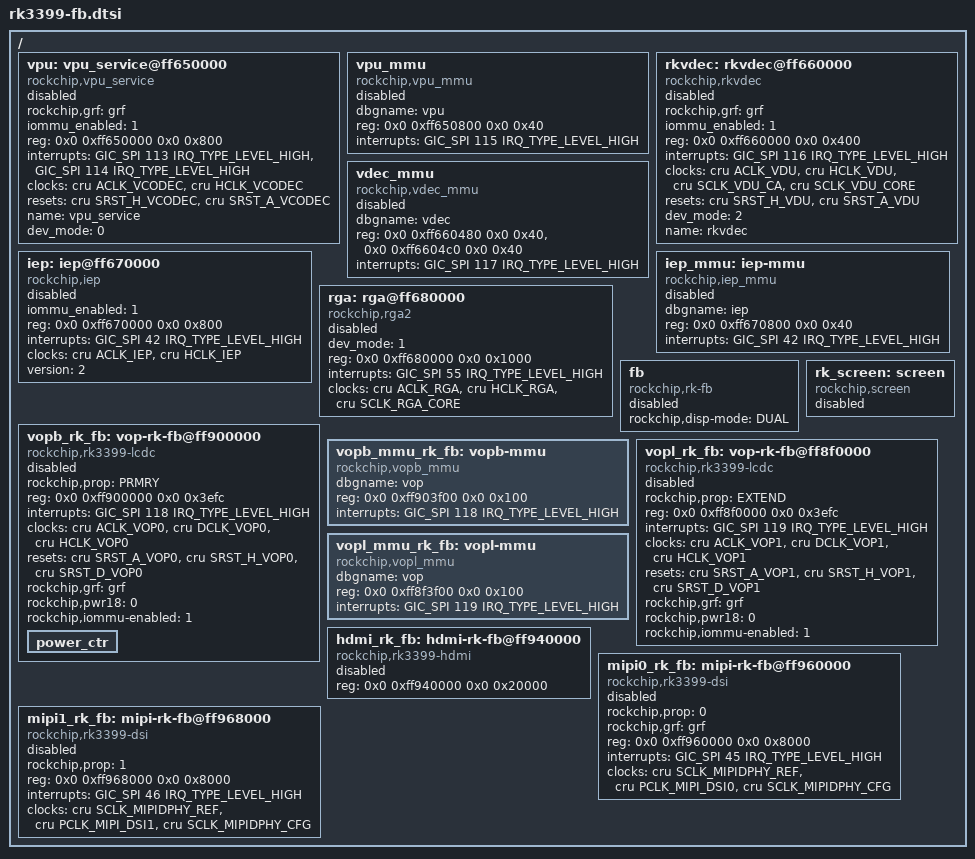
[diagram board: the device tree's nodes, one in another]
/*
 * Copyright (c) 2016 Fuzhou Rockchip Electronics Co., Ltd
 *
 * This file is dual-licensed: you can use it either under the terms
 * of the GPL or the X11 license, at your option. Note that this dual
 * licensing only applies to this file, and not this project as a
 * whole.
 *
 *  a) This file is free software; you can redistribute it and/or
 *     modify it under the terms of the GNU General Public License as
 *     published by the Free Software Foundation; either version 2 of the
 *     License, or (at your option) any later version.
 *
 *     This file is distributed in the hope that it will be useful,
 *     but WITHOUT ANY WARRANTY; without even the implied warranty of
 *     MERCHANTABILITY or FITNESS FOR A PARTICULAR PURPOSE.  See the
 *     GNU General Public License for more details.
 *
 * Or, alternatively,
 *
 *  b) Permission is hereby granted, free of charge, to any person
 *     obtaining a copy of this software and associated documentation
 *     files (the "Software"), to deal in the Software without
 *     restriction, including without limitation the rights to use,
 *     copy, modify, merge, publish, distribute, sublicense, and/or
 *     sell copies of the Software, and to permit persons to whom the
 *     Software is furnished to do so, subject to the following
 *     conditions:
 *
 *     The above copyright notice and this permission notice shall be
 *     included in all copies or substantial portions of the Software.
 *
 *     THE SOFTWARE IS PROVIDED "AS IS", WITHOUT WARRANTY OF ANY KIND,
 *     EXPRESS OR IMPLIED, INCLUDING BUT NOT LIMITED TO THE WARRANTIES
 *     OF MERCHANTABILITY, FITNESS FOR A PARTICULAR PURPOSE AND
 *     NONINFRINGEMENT. IN NO EVENT SHALL THE AUTHORS OR COPYRIGHT
 *     HOLDERS BE LIABLE FOR ANY CLAIM, DAMAGES OR OTHER LIABILITY,
 *     WHETHER IN AN ACTION OF CONTRACT, TORT OR OTHERWISE, ARISING
 *     FROM, OUT OF OR IN CONNECTION WITH THE SOFTWARE OR THE USE OR
 *     OTHER DEALINGS IN THE SOFTWARE.
 */
#include <dt-bindings/display/rk_fb.h>
#include <dt-bindings/display/mipi_dsi.h>

/ {
	vpu: vpu_service@ff650000 {
		compatible = "rockchip,vpu_service";
		rockchip,grf = <&grf>;
		iommu_enabled = <1>;
		reg = <0x0 0xff650000 0x0 0x800>;
		interrupts = <GIC_SPI 113 IRQ_TYPE_LEVEL_HIGH>,
			<GIC_SPI 114 IRQ_TYPE_LEVEL_HIGH>;
		interrupt-names = "irq_dec", "irq_enc";
		clocks = <&cru ACLK_VCODEC>, <&cru HCLK_VCODEC>;
		clock-names = "aclk_vcodec", "hclk_vcodec";
		resets = <&cru SRST_H_VCODEC>, <&cru SRST_A_VCODEC>;
		reset-names = "video_h", "video_a";
		name = "vpu_service";
		dev_mode = <0>;
		status = "disabled";
	};

	vpu_mmu: vpu_mmu {
		dbgname = "vpu";
		compatible = "rockchip,vpu_mmu";
		reg = <0x0 0xff650800 0x0 0x40>;
		interrupts = <GIC_SPI 115 IRQ_TYPE_LEVEL_HIGH>;
		interrupt-names = "vpu_mmu";
		status = "disabled";
	};

	rkvdec: rkvdec@ff660000 {
		compatible = "rockchip,rkvdec";
		rockchip,grf = <&grf>;
		iommu_enabled = <1>;
		reg = <0x0 0xff660000 0x0 0x400>;
		interrupts = <GIC_SPI 116 IRQ_TYPE_LEVEL_HIGH>;
		interrupt-names = "irq_dec";
		clocks = <&cru ACLK_VDU>, <&cru HCLK_VDU>,<&cru SCLK_VDU_CA>,<&cru SCLK_VDU_CORE>;
		clock-names = "aclk_vcodec", "hclk_vcodec", "clk_cabac", "clk_core";
		resets = <&cru SRST_H_VDU>, <&cru SRST_A_VDU>;
		reset-names = "video_h", "video_a";
		dev_mode = <2>;
		name = "rkvdec";
		status = "disabled";
	};

	vdec_mmu: vdec_mmu {
		dbgname = "vdec";
		compatible = "rockchip,vdec_mmu";
		reg = <0x0 0xff660480 0x0 0x40>,
		      <0x0 0xff6604c0 0x0 0x40>;
		interrupts = <GIC_SPI 117 IRQ_TYPE_LEVEL_HIGH>;
		interrupt-names = "vdec_mmu";
		status = "disabled";
	};

	iep: iep@ff670000 {
		compatible = "rockchip,iep";
		iommu_enabled = <1>;
		reg = <0x0 0xff670000 0x0 0x800>;
		interrupts = <GIC_SPI 42 IRQ_TYPE_LEVEL_HIGH>;
		clocks = <&cru ACLK_IEP>, <&cru HCLK_IEP>;
		clock-names = "aclk_iep", "hclk_iep";
		version = <2>;
		status = "disabled";
	};

	iep_mmu: iep-mmu {
		dbgname = "iep";
		compatible = "rockchip,iep_mmu";
		reg = <0x0 0xff670800 0x0 0x40>;
		interrupts = <GIC_SPI 42 IRQ_TYPE_LEVEL_HIGH>;
		interrupt-names = "iep_mmu";
		status = "disabled";
	};

	rga: rga@ff680000 {
		compatible = "rockchip,rga2";
		dev_mode = <1>;
		reg = <0x0 0xff680000 0x0 0x1000>;
		interrupts = <GIC_SPI 55 IRQ_TYPE_LEVEL_HIGH>;
		clocks = <&cru ACLK_RGA>, <&cru HCLK_RGA>, <&cru SCLK_RGA_CORE>;
		clock-names = "aclk_rga", "hclk_rga", "clk_rga";
		status = "disabled";
	};

	fb: fb {
		compatible = "rockchip,rk-fb";
		rockchip,disp-mode = <DUAL>;
		status = "disabled";
	};

	rk_screen: screen {
		compatible = "rockchip,screen";
		status = "disabled";
	};

	vopb_rk_fb: vop-rk-fb@ff900000 {
		status = "disabled";
		compatible = "rockchip,rk3399-lcdc";
		rockchip,prop = <PRMRY>;
		reg = <0x0 0xff900000 0x0 0x3efc>;
		interrupts = <GIC_SPI 118 IRQ_TYPE_LEVEL_HIGH>;
		clocks = <&cru ACLK_VOP0>, <&cru DCLK_VOP0>, <&cru HCLK_VOP0>;
		clock-names = "aclk_lcdc", "dclk_lcdc", "hclk_lcdc";
		resets = <&cru SRST_A_VOP0>, <&cru SRST_H_VOP0>, <&cru SRST_D_VOP0>;
		reset-names = "axi", "ahb", "dclk";
		rockchip,grf = <&grf>;
		rockchip,pwr18 = <0>;
		rockchip,iommu-enabled = <1>;
		power_ctr: power_ctr {
		/*rockchip,debug = <0>;
		lcd_en: lcd-en {
			rockchip,power_type = <GPIO>;
			gpios = <&gpio1 13 GPIO_ACTIVE_HIGH>;//GPIO_C6 = 22
			rockchip,delay = <10>;
		};
		*/

		/*lcd_cs: lcd-cs {
			rockchip,power_type = <GPIO>;
			gpios = <&gpio0 21 GPIO_ACTIVE_HIGH>;//GPIO_C5 = 21
			rockchip,delay = <10>;
		};*/

		/*lcd_rst: lcd-rst {
			rockchip,power_type = <GPIO>;
			gpios = <&gpio3 GPIO_D6 GPIO_ACTIVE_HIGH>;
			rockchip,delay = <5>;
		};*/
		};
	};

	vopb_mmu_rk_fb: vopb-mmu {
		dbgname = "vop";
		compatible = "rockchip,vopb_mmu";
		reg = <0x0 0xff903f00 0x0 0x100>;
		interrupts = <GIC_SPI 118 IRQ_TYPE_LEVEL_HIGH>;
		interrupt-names = "vopb_mmu";
		status = "okay";
	};

	vopl_rk_fb: vop-rk-fb@ff8f0000 {
		compatible = "rockchip,rk3399-lcdc";
		rockchip,prop = <EXTEND>;
		reg = <0x0 0xff8f0000 0x0 0x3efc>;
		interrupts = <GIC_SPI 119 IRQ_TYPE_LEVEL_HIGH>;
		clocks = <&cru ACLK_VOP1>, <&cru DCLK_VOP1>, <&cru HCLK_VOP1>;
		clock-names = "aclk_lcdc", "dclk_lcdc", "hclk_lcdc";
		resets = <&cru SRST_A_VOP1>, <&cru SRST_H_VOP1>, <&cru SRST_D_VOP1>;
		reset-names = "axi", "ahb", "dclk";
		rockchip,grf = <&grf>;
		rockchip,pwr18 = <0>;
		rockchip,iommu-enabled = <1>;
		status = "disabled";
	};

	vopl_mmu_rk_fb: vopl-mmu {
		dbgname = "vop";
		compatible = "rockchip,vopl_mmu";
		reg = <0x0 0xff8f3f00 0x0 0x100>;
		interrupts = <GIC_SPI 119 IRQ_TYPE_LEVEL_HIGH>;
		interrupt-names = "vopl_mmu";
		status = "okay";
	};

	hdmi_rk_fb: hdmi-rk-fb@ff940000 {
		compatible = "rockchip,rk3399-hdmi";
		reg = <0x0 0xff940000 0x0 0x20000>;
		status = "disabled";
	};

	mipi0_rk_fb: mipi-rk-fb@ff960000 {
		compatible = "rockchip,rk3399-dsi";
		rockchip,prop = <0>;
		rockchip,grf = <&grf>;
		reg = <0x0 0xff960000 0x0 0x8000>;
		interrupts = <GIC_SPI 45 IRQ_TYPE_LEVEL_HIGH>;
		clocks = <&cru SCLK_MIPIDPHY_REF>, <&cru PCLK_MIPI_DSI0>, <&cru SCLK_MIPIDPHY_CFG>;
		clock-names = "clk_mipi_24m", "pclk_mipi_dsi", "mipi_dphy_cfg";
		status = "disabled";
	};

	mipi1_rk_fb: mipi-rk-fb@ff968000 {
		compatible = "rockchip,rk3399-dsi";
		rockchip,prop = <1>;
		reg = <0x0 0xff968000 0x0 0x8000>;
		interrupts = <GIC_SPI 46 IRQ_TYPE_LEVEL_HIGH>;
		clocks = <&cru SCLK_MIPIDPHY_REF>, <&cru PCLK_MIPI_DSI1>, <&cru SCLK_MIPIDPHY_CFG>;
		clock-names = "clk_mipi_24m", "pclk_mipi_dsi", "mipi_dphy_cfg";
		status = "disabled";
	};
};
